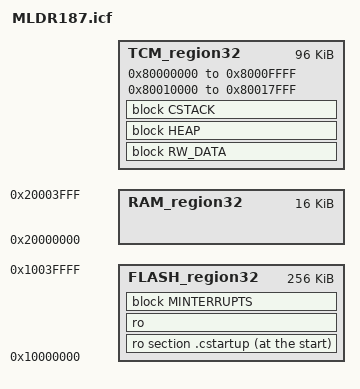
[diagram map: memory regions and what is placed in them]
///////////////////////////////////////////////////////////////////////////////
//
// IAR ILINK Linker configuration file for the Milandr MLDR187
// development board with the CloudBEAr BM-310S processor.core.
//

define exported symbol _link_file_version_2 = 1;

define memory mem with size = 4G;

define region FLASH_region32 = 	mem:[from 0x10000000 to 0x1003FFFF];
define region TCM_region32 = 	mem:[from 0x80000000 to 0x8000FFFF] | mem:[from 0x80010000 to 0x80017FFF];
/*
define region TCMA_region32 = 	mem:[from 0x80000000 to 0x8000FFFF];
define region TCMB_region32 = 	mem:[from 0x80010000 to 0x80017FFF];
*/
define region RAM_region32 = 	mem:[from 0x20000000 to 0x20003FFF];

initialize by copy { rw };
do not initialize  { section *.noinit };

define block CSTACK with alignment = 16, size = CSTACK_SIZE { };
define block HEAP   with alignment = 16, size = HEAP_SIZE   { };

define block MVECTOR with alignment = 128 { ro section .mintvec };

if (isdefinedsymbol(_uses_clic))
{
  define block MINTERRUPT with alignment = 128 { ro section .mtext };
  define block MINTERRUPTS { block MVECTOR,
                             block MINTERRUPT };
}
else
{
  define block MINTERRUPTS with maximum size =  64k { ro section .mtext,
                                                      midway block MVECTOR };
}

define block RW_DATA with static base GPREL { rw data };
keep { symbol __iar_cstart_init_gp }; // defined in cstartup.s

"CSTARTUP32" : place at start of FLASH_region32 { ro section .cstartup };

"ROM32":place in FLASH_region32       { ro,
                                        block MINTERRUPTS };

"RAM32":place in TCM_region32         { block RW_DATA,
                                        block HEAP,
                                        block CSTACK };
                                        
"RAM32":place in RAM_region32         { };
